# M411_unitB register map
File version: 2.0.2.2
Registers are 32-bit, read-write, no defined reset value unless marked. A register's access mark holds for its fields unless they carry their own. Offsets are from the block's base; [hi:lo] are bit positions; {n}, {i} and the like mark numbered series.

## DMA — DMA Controller (DMA)
Base 0x4004D000
0x00 STATUS ro reset 0x101F0000 — DMA Status Register
  [0] MASTER_ENABLE
0x04 CFG wo — DMA Configuration Register
  [0] MASTER_ENABLE
0x08 CTRLBASEPTR reset 0x0 — DMA Control Data Base Pointer Register
  [31:10] CTRL_BASE_PTR
0x0C ALTCTRLBASEPTR ro reset 0x0 — DMA Channel Alternate Control Data Base Pointer Register
  [31:0] ALT_CTRL_BASE_PTR
0x14 CHNLSWREQUEST wo — DMA Channel Software Request Register
  [31:0] CHNL_SW_REQUEST
0x18 CHNLUSEBURSTSET reset 0x0 — DMA Channel Useburst Set Register
  [31:0] CHNL_USEBURST_SET
0x1C CHNLUSEBURSTCLR wo — DMA Channel Useburst Clear Register
  [31:0] CHNL_USEBURST_CLR
0x20 CHNLREQMASKSET reset 0x0 — DMA Channel Request Mask Set Register
  [31:0] CHNL_REQ_MASK_SET
0x24 CHNLREQMASKCLR wo — DMA Channel Request Mask Clear Register
  [31:0] CHNL_REQ_MASK_CLR
0x28 CHNLENABLESET reset 0x0 — DMA Channel Enable Set Register
  [31:0] CHNL_ENABLE_SET
0x2C CHNLENABLECLR wo — DMA Channel Enable Clear Register
  [31:0] CHNL_ENABLE_CLR
0x30 CHNLPRIALTSET reset 0x0 — DMA Channel Primary-Alternate Set Register
  [31:0] CHNL_PRI_ALT_SET
0x34 CHNLPRIALTCLR wo — DMA Channel Primary-Alternate Clear Register
  [31:0] CHNL_PRI_ALT_CLR
0x38 CHNLPRIORITYSET reset 0x0 — DMA Channel Priority Set Register
  [31:0] CHNL_PRIORITY_SET
0x3C CHNLPRIORITYCLR wo — DMA Channel Priority Clear Register
  [31:0] CHNL_PRIORITY_CLR
0x4C ERRCLR reset 0x0 — DMA Bus Error Clear Register
  [0] ERR_CLR

## AD — 12bit A_D Converter (AD)
Base 0x40051000
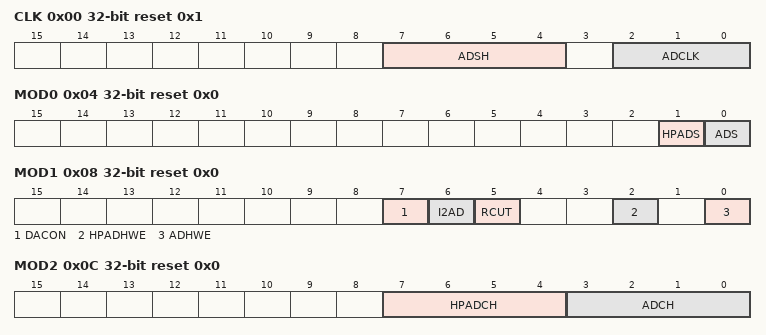
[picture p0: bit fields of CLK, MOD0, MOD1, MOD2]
0x00 CLK reset 0x1 — Conversion Clock Setting Register
  [7:4] ADSH, [2:0] ADCLK
0x04 MOD0 wo reset 0x0 — Mode Control Register0
  [1] HPADS, [0] ADS
0x08 MOD1 reset 0x0 — Mode Control Register1
  [7] DACON, [6] I2AD, [5] RCUT, [2] HPADHWE, [0] ADHWE
0x0C MOD2 reset 0x0 — Mode Control Register2
  [7:4] HPADCH, [3:0] ADCH
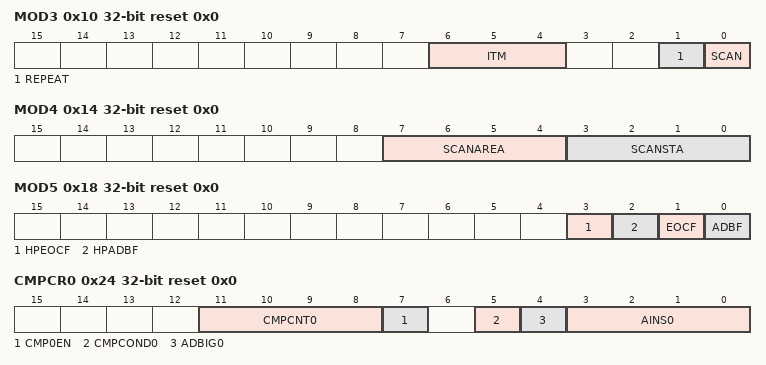
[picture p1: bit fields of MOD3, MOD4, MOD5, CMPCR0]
0x10 MOD3 reset 0x0 — Mode Control Register3
  [6:4] ITM, [1] REPEAT, [0] SCAN
0x14 MOD4 reset 0x0 — Mode Control Register4
  [7:4] SCANAREA, [3:0] SCANSTA
0x18 MOD5 ro reset 0x0 — Mode Control Register5
  [3] HPEOCF, [2] HPADBF, [1] EOCF, [0] ADBF
0x1C MOD6 wo reset 0x0 — Mode Control Register6
  [1:0] ADRST
0x24 CMPCR0 reset 0x0 — Monitoring Interrupt Control Register0
  [11:8] CMPCNT0, [7] CMP0EN, [5] CMPCOND0, [4] ADBIG0, [3:0] AINS0
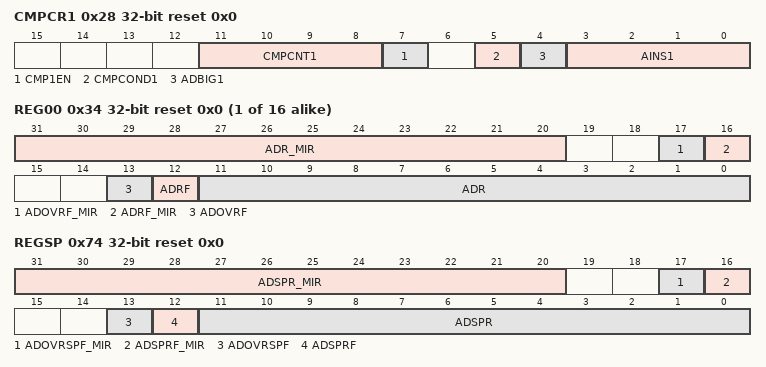
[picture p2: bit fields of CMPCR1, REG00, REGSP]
0x28 CMPCR1 reset 0x0 — Monitoring Interrupt Control Register1
  [11:8] CMPCNT1, [7] CMP1EN, [5] CMPCOND1, [4] ADBIG1, [3:0] AINS1
0x2C CMP0 reset 0x0 — Conversion Result Compare Register0
  [11:0] AD0CMP
0x30 CMP1 reset 0x0 — Conversion Result Compare Register1
  [11:0] AD1CMP
{0x34+4i} REG{i:02} ro reset 0x0 (i=0..15) — Conversion Result Store Register{i}
  [31:20] ADR_MIR, [17] ADOVRF_MIR, [16] ADRF_MIR, [13] ADOVRF, [12] ADRF, [11:0] ADR
0x74 REGSP ro reset 0x0 — Highest Priority Conversion Result Store Register
  [31:20] ADSPR_MIR, [17] ADOVRSPF_MIR, [16] ADSPRF_MIR, [13] ADOVRSPF, [12] ADSPRF, [11:0] ADSPR

## T16A2 — 16-bit TimerA (T16A)
Base 0x4008F000
Same registers: T16A3 0x40090000
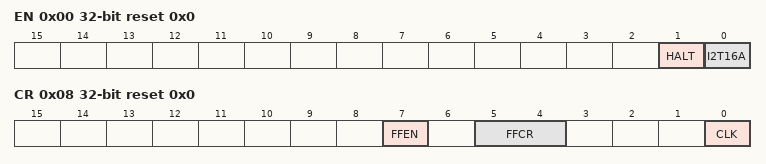
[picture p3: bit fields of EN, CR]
0x00 EN reset 0x0 — Enable Register
  [1] HALT, [0] I2T16A
0x04 RUN reset 0x0
  [0] RUN
0x08 CR reset 0x0 — Control Register
  [7] FFEN, [5:4] FFCR wo, [0] CLK
0x0C RG reset 0x0 — Timer Register
  [15:0] RG
0x10 CP ro reset 0x0 — Capture Register
  [15:0] CP

## INT — Interrupt Controller (INT)
Base 0x400B8100
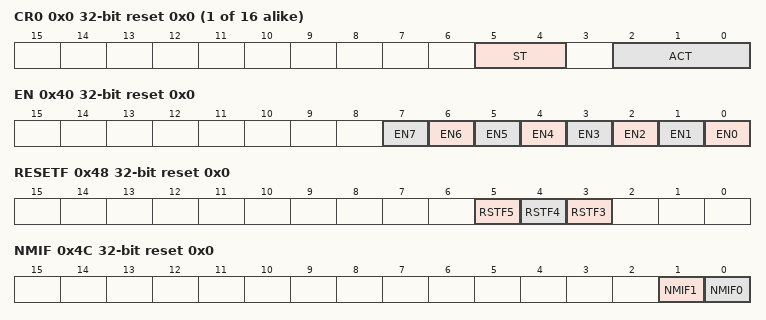
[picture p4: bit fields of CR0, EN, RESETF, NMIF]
{0x0+4i} CR{i} reset 0x0 (i=0..15) — Control Register {i}
  [5:4] ST ro, [2:0] ACT
0x40 EN reset 0x0 — STOP1 Mode Release Setting Register
  [n] EN{n} (n=0..7)
0x44 CLR wo reset 0x0 — Interrupt Request Clear Register
  [3:0] CLR
0x48 RESETF reset 0x0 — Reset Flag Register
  [5] RSTF5, [4] RSTF4, [3] RSTF3
0x4C NMIF ro reset 0x0 — NMI Flag Register
  [1] NMIF1, [0] NMIF0
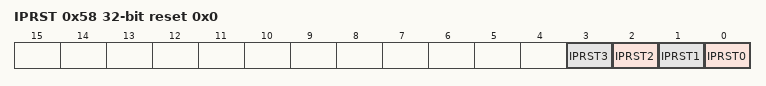
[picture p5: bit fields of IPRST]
0x58 IPRST reset 0x0 — Peripheral Function Reset Register
  [n] IPRST{n} (n=0..3)
